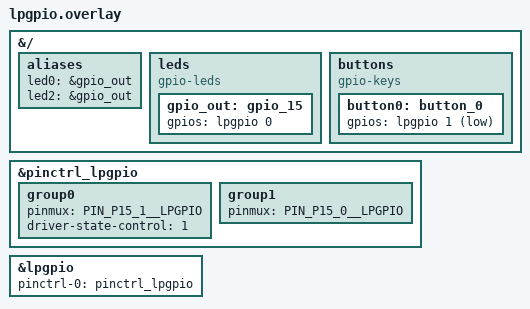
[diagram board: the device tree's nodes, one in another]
/* Copyright (C) Alif Semiconductor - All Rights Reserved.
 * Use, distribution and modification of this code is permitted under the
 * terms stated in the Alif Semiconductor Software License Agreement
 *
 * You should have received a copy of the Alif Semiconductor Software
 * License Agreement with this file. If not, please write to:
 * contact@alifsemi.com, or visit: https://alifsemi.com/license
 */


&{/} {
	aliases {
		led0 = &gpio_out;
		led2 = &gpio_out;
	};

	leds {
		compatible = "gpio-leds";
		gpio_out: gpio_15 {
			gpios = <&lpgpio 0 0>;
		};
	};

	/delete-node/ buttons;

	buttons {
		compatible = "gpio-keys";
		button0: button_0 {
			gpios = <&lpgpio 1 GPIO_ACTIVE_LOW>;
		};
	};
};


&pinctrl_lpgpio {
	group0 {
		pinmux = <PIN_P15_1__LPGPIO>;
		driver-state-control = <1>;
	};
	group1 {
		pinmux = <PIN_P15_0__LPGPIO>;
	};
};

&lpgpio {
	pinctrl-0 = < &pinctrl_lpgpio >;
	pinctrl-names = "default";
	status = "okay";
};
